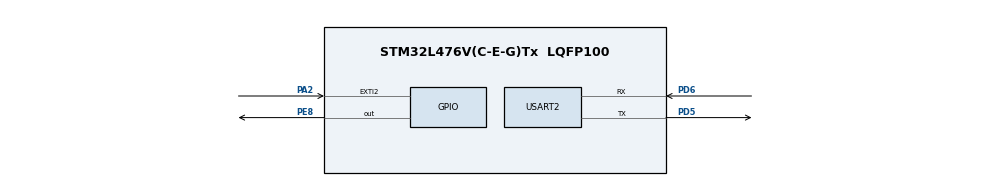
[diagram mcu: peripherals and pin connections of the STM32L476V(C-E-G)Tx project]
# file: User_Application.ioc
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Mcu.Family=STM32L4
Mcu.Name=STM32L476V(C-E-G)Tx
Mcu.Package=LQFP100
NVIC.EXTI2_IRQn=true\:15\:0\:true\:false\:true\:true\:true
NVIC.PriorityGroup=NVIC_PRIORITYGROUP_4
PA2.GPIO_PuPd=GPIO_PULLDOWN
PA2.Signal=GPXTI2
PD5.Mode=Asynchronous
PD5.Signal=USART2_TX
PD6.Mode=Asynchronous
PD6.Signal=USART2_RX
PE8.Signal=GPIO_Output
ProjectManager.HeapSize=0x200
ProjectManager.StackSize=0x400
ProjectManager.TargetToolchain=SW4STM32
RCC.HSE_VALUE=8000000
RCC.HSI_VALUE=16000000
RCC.LSE_VALUE=32768
RCC.MSI_VALUE=4000000
RCC.VCOOutputFreq_Value=32000000
USART2.VirtualMode-Asynchronous=VM_ASYNC
board=custom

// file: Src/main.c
/* USER CODE BEGIN Header */
/**
  ******************************************************************************
  * @file           : main.c
  * @brief          : Main program body
  ******************************************************************************
  * @attention
  *
  * <h2><center>&copy; Copyright (c) 2020 STMicroelectronics.
  * All rights reserved.</center></h2>
  *
  * This software component is licensed by ST under BSD 3-Clause license,
  * the "License"; You may not use this file except in compliance with the
  * License. You may obtain a copy of the License at:
  *                        opensource.org/licenses/BSD-3-Clause
  *
  ******************************************************************************
  */
/* USER CODE END Header */

#include "main.h"

UART_HandleTypeDef huart2;

void SystemClock_Config(void);
static void MX_GPIO_Init(void);
static void MX_USART2_UART_Init(void);

int main(void)
{
  /* USER CODE BEGIN 1 */
	char somedata[] = "User Application running\r\n";
  /* USER CODE END 1 */

  /* MCU Configuration--------------------------------------------------------*/

  /* Reset of all peripherals, Initializes the Flash interface and the Systick. */
  HAL_Init();

  /* Configure the system clock */
  SystemClock_Config();

  /* Initialize all configured peripherals */
  MX_GPIO_Init();
  MX_USART2_UART_Init();

  /* Infinite loop */
  while (1)
  {
	  HAL_UART_Transmit(&huart2, (uint8_t *)somedata,sizeof(somedata), HAL_MAX_DELAY);
	  HAL_Delay(1000);
  }
}

void SystemClock_Config(void)
{
  RCC_OscInitTypeDef RCC_OscInitStruct = {0};
  RCC_ClkInitTypeDef RCC_ClkInitStruct = {0};
  RCC_PeriphCLKInitTypeDef PeriphClkInit = {0};

  /** Initializes the CPU, AHB and APB busses clocks
  */
  RCC_OscInitStruct.OscillatorType = RCC_OSCILLATORTYPE_MSI;
  RCC_OscInitStruct.MSIState = RCC_MSI_ON;
  RCC_OscInitStruct.MSICalibrationValue = 0;
  RCC_OscInitStruct.MSIClockRange = RCC_MSIRANGE_6;
  RCC_OscInitStruct.PLL.PLLState = RCC_PLL_NONE;
  if (HAL_RCC_OscConfig(&RCC_OscInitStruct) != HAL_OK)
  {
    Error_Handler();
  }
  /** Initializes the CPU, AHB and APB busses clocks
  */
  RCC_ClkInitStruct.ClockType = RCC_CLOCKTYPE_HCLK|RCC_CLOCKTYPE_SYSCLK
                              |RCC_CLOCKTYPE_PCLK1|RCC_CLOCKTYPE_PCLK2;
  RCC_ClkInitStruct.SYSCLKSource = RCC_SYSCLKSOURCE_MSI;
  RCC_ClkInitStruct.AHBCLKDivider = RCC_SYSCLK_DIV1;
  RCC_ClkInitStruct.APB1CLKDivider = RCC_HCLK_DIV1;
  RCC_ClkInitStruct.APB2CLKDivider = RCC_HCLK_DIV1;

  if (HAL_RCC_ClockConfig(&RCC_ClkInitStruct, FLASH_LATENCY_0) != HAL_OK)
  {
    Error_Handler();
  }
  PeriphClkInit.PeriphClockSelection = RCC_PERIPHCLK_USART2;
  PeriphClkInit.Usart2ClockSelection = RCC_USART2CLKSOURCE_PCLK1;
  if (HAL_RCCEx_PeriphCLKConfig(&PeriphClkInit) != HAL_OK)
  {
    Error_Handler();
  }
  /** Configure the main internal regulator output voltage
  */
  if (HAL_PWREx_ControlVoltageScaling(PWR_REGULATOR_VOLTAGE_SCALE1) != HAL_OK)
  {
    Error_Handler();
  }
}

static void MX_USART2_UART_Init(void)
{

  huart2.Instance = USART2;
  huart2.Init.BaudRate = 115200;
  huart2.Init.WordLength = UART_WORDLENGTH_8B;
  huart2.Init.StopBits = UART_STOPBITS_1;
  huart2.Init.Parity = UART_PARITY_NONE;
  huart2.Init.Mode = UART_MODE_TX_RX;
  huart2.Init.HwFlowCtl = UART_HWCONTROL_NONE;
  huart2.Init.OverSampling = UART_OVERSAMPLING_16;
  huart2.Init.OneBitSampling = UART_ONE_BIT_SAMPLE_DISABLE;
  huart2.AdvancedInit.AdvFeatureInit = UART_ADVFEATURE_NO_INIT;
  if (HAL_UART_Init(&huart2) != HAL_OK)
  {
    Error_Handler();
  }

}

static void MX_GPIO_Init(void)
{
  GPIO_InitTypeDef GPIO_InitStruct = {0};

  /* GPIO Ports Clock Enable */
  __HAL_RCC_GPIOA_CLK_ENABLE();
  __HAL_RCC_GPIOE_CLK_ENABLE();
  __HAL_RCC_GPIOD_CLK_ENABLE();

  /*Configure GPIO pin Output Level */
  HAL_GPIO_WritePin(GPIOE, GPIO_PIN_8, GPIO_PIN_RESET);

  /*Configure GPIO pin : PA2 */
  GPIO_InitStruct.Pin = GPIO_PIN_2;
  GPIO_InitStruct.Mode = GPIO_MODE_IT_RISING;
  GPIO_InitStruct.Pull = GPIO_PULLDOWN;
  HAL_GPIO_Init(GPIOA, &GPIO_InitStruct);

  /*Configure GPIO pin : PE8 */
  GPIO_InitStruct.Pin = GPIO_PIN_8;
  GPIO_InitStruct.Mode = GPIO_MODE_OUTPUT_PP;
  GPIO_InitStruct.Pull = GPIO_NOPULL;
  GPIO_InitStruct.Speed = GPIO_SPEED_FREQ_LOW;
  HAL_GPIO_Init(GPIOE, &GPIO_InitStruct);

  /* EXTI interrupt init*/
  HAL_NVIC_SetPriority(EXTI2_IRQn, 15, 0);
  HAL_NVIC_EnableIRQ(EXTI2_IRQn);

}

void Error_Handler(void)
{
}

/************************ (C) COPYRIGHT STMicroelectronics *****END OF FILE****/
